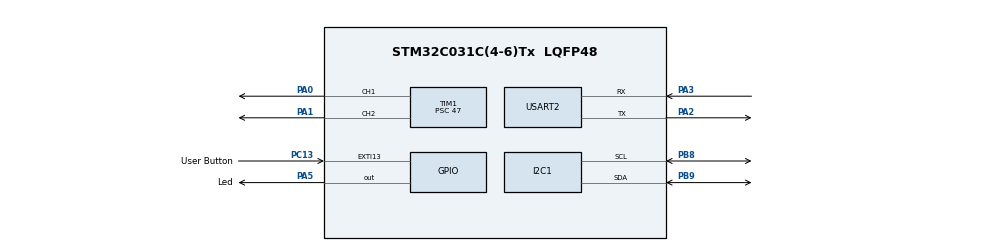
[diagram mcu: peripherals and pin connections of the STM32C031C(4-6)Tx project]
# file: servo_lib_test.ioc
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I2C1.Timing=0x20303E5D
Mcu.Family=STM32C0
Mcu.Name=STM32C031C(4-6)Tx
Mcu.Package=LQFP48
NVIC.EXTI4_15_IRQn=true\:0\:0\:false\:false\:true\:true\:true\:true
PA0.Signal=S_TIM1_CH1
PA1.Signal=S_TIM1_CH2
PA13.Mode=Serial_Wire
PA13.Signal=DEBUG_SWDIO
PA14-BOOT0.Mode=Serial_Wire
PA14-BOOT0.Signal=DEBUG_SWCLK
PA2.Mode=Asynchronous
PA2.Signal=USART2_TX
PA3.Mode=Asynchronous
PA3.Signal=USART2_RX
PA5.GPIO_Label=Led
PA5.GPIO_Speed=GPIO_SPEED_FREQ_VERY_HIGH
PA5.PinState=GPIO_PIN_SET
PA5.Signal=GPIO_Output
PB8.Mode=I2C
PB8.Signal=I2C1_SCL
PB9.Mode=I2C
PB9.Signal=I2C1_SDA
PC13.GPIO_Label=User Button
PC13.Signal=GPXTI13
PC14-OSCX_IN\ (PC14).Mode=LSE-External-Oscillator
PC14-OSCX_IN\ (PC14).Signal=RCC_OSCX_IN
PC15-OSCX_OUT\ (PC15).Mode=LSE-External-Oscillator
PC15-OSCX_OUT\ (PC15).Signal=RCC_OSCX_OUT
PF0-OSC_IN\ (PF0).Mode=HSE-External-Oscillator
PF0-OSC_IN\ (PF0).Signal=RCC_OSC_IN
PF1-OSC_OUT\ (PF1).Mode=HSE-External-Oscillator
PF1-OSC_OUT\ (PF1).Signal=RCC_OSC_OUT
ProjectManager.HeapSize=0x200
ProjectManager.StackSize=0x400
ProjectManager.TargetToolchain=STM32CubeIDE
RCC.ADCFreq_Value=48000000
RCC.AHBFreq_Value=48000000
RCC.CortexFreq_Value=48000000
RCC.EXTERNAL_CLOCK_VALUE=12288000
RCC.HCLKFreq_Value=48000000
RCC.HSE_VALUE=48000000
RCC.HSISYSCLKDivider=RCC_HSI_DIV1
RCC.HSI_VALUE=48000000
RCC.SYSCLKFreq_VALUE=48000000
SH.S_TIM1_CH1.0=TIM1_CH1,PWM Generation1 CH1
SH.S_TIM1_CH2.0=TIM1_CH2,PWM Generation2 CH2
TIM1.Channel-PWM\ Generation1\ CH1=TIM_CHANNEL_1
TIM1.Channel-PWM\ Generation2\ CH2=TIM_CHANNEL_2
TIM1.Period=256
TIM1.Prescaler=47
TIM1.Pulse-PWM\ Generation1\ CH1=0
TIM1.Pulse-PWM\ Generation2\ CH2=0
USART2.VirtualMode-Asynchronous=VM_ASYNC
VP_TIM1_VS_ClockSourceINT.Mode=Internal
board=NUCLEO-C031C6

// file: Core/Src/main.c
/* USER CODE BEGIN Header */
/**
  ******************************************************************************
  * @file           : main.c
  * @brief          : Main program body
  ******************************************************************************
  * @attention
  *
  * Copyright (c) 2024 STMicroelectronics.
  * All rights reserved.
  *
  * This software is licensed under terms that can be found in the LICENSE file
  * in the root directory of this software component.
  * If no LICENSE file comes with this software, it is provided AS-IS.
  *
  ******************************************************************************
  */
/* USER CODE END Header */
#include "main.h"

/* USER CODE BEGIN Includes */
#include "servo.h"
/* USER CODE END Includes */

I2C_HandleTypeDef hi2c1;

TIM_HandleTypeDef htim1;

UART_HandleTypeDef huart2;

void SystemClock_Config(void);
static void MX_GPIO_Init(void);
static void MX_USART2_UART_Init(void);
static void MX_I2C1_Init(void);
static void MX_TIM1_Init(void);

/* USER CODE BEGIN 0 */
uint32_t pwm1, cycle = 4096, pwm2;
Servo myServo1, myServo2;
/* USER CODE END 0 */

int main(void)
{

  /* MCU Configuration--------------------------------------------------------*/

  /* Reset of all peripherals, Initializes the Flash interface and the Systick. */
  HAL_Init();

  /* Configure the system clock */
  SystemClock_Config();

  /* Initialize all configured peripherals */
  MX_GPIO_Init();
  MX_USART2_UART_Init();
  MX_I2C1_Init();
  MX_TIM1_Init();
  /* USER CODE BEGIN 2 */
  SERVO_INIT(&htim1, cycle);
  Servo_Start(&myServo1, TIM_CHANNEL_1);
  Servo_Start(&myServo2, TIM_CHANNEL_2);
  /* USER CODE END 2 */

  /* Infinite loop */
  /* USER CODE BEGIN WHILE */
  //HAL_TIM_Base_Start(&htim1);
	//HAL_TIM_PWM_Start(&htim1, TIM_CHANNEL_1);
	//HAL_TIM_PWM_Start(&htim1, TIM_CHANNEL_2);
	//HAL_TIM_PWM_Start_DMA(&htim1, TIM_CHANNEL_1, &pwm1, 1);
  while (1)
  {
	  Servo_Write(&myServo1, pwm1);
	  Servo_Write(&myServo2, pwm2);
	  //SERVO_SET_DUTY_CYCLE(cycle);
    /* USER CODE END WHILE */

  }
}

void SystemClock_Config(void)
{
  RCC_OscInitTypeDef RCC_OscInitStruct = {0};
  RCC_ClkInitTypeDef RCC_ClkInitStruct = {0};

  /** Initializes the RCC Oscillators according to the specified parameters
  * in the RCC_OscInitTypeDef structure.
  */
  RCC_OscInitStruct.OscillatorType = RCC_OSCILLATORTYPE_HSI;
  RCC_OscInitStruct.HSIState = RCC_HSI_ON;
  RCC_OscInitStruct.HSIDiv = RCC_HSI_DIV1;
  RCC_OscInitStruct.HSICalibrationValue = RCC_HSICALIBRATION_DEFAULT;
  if (HAL_RCC_OscConfig(&RCC_OscInitStruct) != HAL_OK)
  {
    Error_Handler();
  }

  /** Initializes the CPU, AHB and APB buses clocks
  */
  RCC_ClkInitStruct.ClockType = RCC_CLOCKTYPE_HCLK|RCC_CLOCKTYPE_SYSCLK
                              |RCC_CLOCKTYPE_PCLK1;
  RCC_ClkInitStruct.SYSCLKSource = RCC_SYSCLKSOURCE_HSI;
  RCC_ClkInitStruct.SYSCLKDivider = RCC_SYSCLK_DIV1;
  RCC_ClkInitStruct.AHBCLKDivider = RCC_HCLK_DIV1;
  RCC_ClkInitStruct.APB1CLKDivider = RCC_APB1_DIV1;

  if (HAL_RCC_ClockConfig(&RCC_ClkInitStruct, FLASH_LATENCY_1) != HAL_OK)
  {
    Error_Handler();
  }
}

static void MX_I2C1_Init(void)
{

  hi2c1.Instance = I2C1;
  hi2c1.Init.Timing = 0x20303E5D;
  hi2c1.Init.OwnAddress1 = 0;
  hi2c1.Init.AddressingMode = I2C_ADDRESSINGMODE_7BIT;
  hi2c1.Init.DualAddressMode = I2C_DUALADDRESS_DISABLE;
  hi2c1.Init.OwnAddress2 = 0;
  hi2c1.Init.OwnAddress2Masks = I2C_OA2_NOMASK;
  hi2c1.Init.GeneralCallMode = I2C_GENERALCALL_DISABLE;
  hi2c1.Init.NoStretchMode = I2C_NOSTRETCH_DISABLE;
  if (HAL_I2C_Init(&hi2c1) != HAL_OK)
  {
    Error_Handler();
  }

  /** Configure Analogue filter
  */
  if (HAL_I2CEx_ConfigAnalogFilter(&hi2c1, I2C_ANALOGFILTER_ENABLE) != HAL_OK)
  {
    Error_Handler();
  }

  /** Configure Digital filter
  */
  if (HAL_I2CEx_ConfigDigitalFilter(&hi2c1, 0) != HAL_OK)
  {
    Error_Handler();
  }

}

static void MX_TIM1_Init(void)
{

  TIM_ClockConfigTypeDef sClockSourceConfig = {0};
  TIM_MasterConfigTypeDef sMasterConfig = {0};
  TIM_OC_InitTypeDef sConfigOC = {0};
  TIM_BreakDeadTimeConfigTypeDef sBreakDeadTimeConfig = {0};

  htim1.Instance = TIM1;
  htim1.Init.Prescaler = 47;
  htim1.Init.CounterMode = TIM_COUNTERMODE_UP;
  htim1.Init.Period = 256;
  htim1.Init.ClockDivision = TIM_CLOCKDIVISION_DIV1;
  htim1.Init.RepetitionCounter = 0;
  htim1.Init.AutoReloadPreload = TIM_AUTORELOAD_PRELOAD_DISABLE;
  if (HAL_TIM_Base_Init(&htim1) != HAL_OK)
  {
    Error_Handler();
  }
  sClockSourceConfig.ClockSource = TIM_CLOCKSOURCE_INTERNAL;
  if (HAL_TIM_ConfigClockSource(&htim1, &sClockSourceConfig) != HAL_OK)
  {
    Error_Handler();
  }
  if (HAL_TIM_PWM_Init(&htim1) != HAL_OK)
  {
    Error_Handler();
  }
  sMasterConfig.MasterOutputTrigger = TIM_TRGO_RESET;
  sMasterConfig.MasterOutputTrigger2 = TIM_TRGO2_RESET;
  sMasterConfig.MasterSlaveMode = TIM_MASTERSLAVEMODE_DISABLE;
  if (HAL_TIMEx_MasterConfigSynchronization(&htim1, &sMasterConfig) != HAL_OK)
  {
    Error_Handler();
  }
  sConfigOC.OCMode = TIM_OCMODE_PWM1;
  sConfigOC.Pulse = 0;
  sConfigOC.OCPolarity = TIM_OCPOLARITY_HIGH;
  sConfigOC.OCNPolarity = TIM_OCNPOLARITY_HIGH;
  sConfigOC.OCFastMode = TIM_OCFAST_DISABLE;
  sConfigOC.OCIdleState = TIM_OCIDLESTATE_RESET;
  sConfigOC.OCNIdleState = TIM_OCNIDLESTATE_RESET;
  if (HAL_TIM_PWM_ConfigChannel(&htim1, &sConfigOC, TIM_CHANNEL_1) != HAL_OK)
  {
    Error_Handler();
  }
  if (HAL_TIM_PWM_ConfigChannel(&htim1, &sConfigOC, TIM_CHANNEL_2) != HAL_OK)
  {
    Error_Handler();
  }
  sBreakDeadTimeConfig.OffStateRunMode = TIM_OSSR_DISABLE;
  sBreakDeadTimeConfig.OffStateIDLEMode = TIM_OSSI_DISABLE;
  sBreakDeadTimeConfig.LockLevel = TIM_LOCKLEVEL_OFF;
  sBreakDeadTimeConfig.DeadTime = 0;
  sBreakDeadTimeConfig.BreakState = TIM_BREAK_DISABLE;
  sBreakDeadTimeConfig.BreakPolarity = TIM_BREAKPOLARITY_HIGH;
  sBreakDeadTimeConfig.BreakFilter = 0;
  sBreakDeadTimeConfig.BreakAFMode = TIM_BREAK_AFMODE_INPUT;
  sBreakDeadTimeConfig.Break2State = TIM_BREAK2_DISABLE;
  sBreakDeadTimeConfig.Break2Polarity = TIM_BREAK2POLARITY_HIGH;
  sBreakDeadTimeConfig.Break2Filter = 0;
  sBreakDeadTimeConfig.Break2AFMode = TIM_BREAK_AFMODE_INPUT;
  sBreakDeadTimeConfig.AutomaticOutput = TIM_AUTOMATICOUTPUT_DISABLE;
  if (HAL_TIMEx_ConfigBreakDeadTime(&htim1, &sBreakDeadTimeConfig) != HAL_OK)
  {
    Error_Handler();
  }
  HAL_TIM_MspPostInit(&htim1);

}

static void MX_USART2_UART_Init(void)
{

  huart2.Instance = USART2;
  huart2.Init.BaudRate = 115200;
  huart2.Init.WordLength = UART_WORDLENGTH_8B;
  huart2.Init.StopBits = UART_STOPBITS_1;
  huart2.Init.Parity = UART_PARITY_NONE;
  huart2.Init.Mode = UART_MODE_TX_RX;
  huart2.Init.HwFlowCtl = UART_HWCONTROL_NONE;
  huart2.Init.OverSampling = UART_OVERSAMPLING_16;
  huart2.Init.OneBitSampling = UART_ONE_BIT_SAMPLE_DISABLE;
  huart2.Init.ClockPrescaler = UART_PRESCALER_DIV1;
  huart2.AdvancedInit.AdvFeatureInit = UART_ADVFEATURE_NO_INIT;
  if (HAL_UART_Init(&huart2) != HAL_OK)
  {
    Error_Handler();
  }

}

static void MX_GPIO_Init(void)
{
  GPIO_InitTypeDef GPIO_InitStruct = {0};

  /* GPIO Ports Clock Enable */
  __HAL_RCC_GPIOC_CLK_ENABLE();
  __HAL_RCC_GPIOF_CLK_ENABLE();
  __HAL_RCC_GPIOA_CLK_ENABLE();
  __HAL_RCC_GPIOB_CLK_ENABLE();

  /*Configure GPIO pin Output Level */
  HAL_GPIO_WritePin(Led_GPIO_Port, Led_Pin, GPIO_PIN_SET);

  /*Configure GPIO pin : User_Button_Pin */
  GPIO_InitStruct.Pin = User_Button_Pin;
  GPIO_InitStruct.Mode = GPIO_MODE_IT_RISING;
  GPIO_InitStruct.Pull = GPIO_NOPULL;
  HAL_GPIO_Init(User_Button_GPIO_Port, &GPIO_InitStruct);

  /*Configure GPIO pin : Led_Pin */
  GPIO_InitStruct.Pin = Led_Pin;
  GPIO_InitStruct.Mode = GPIO_MODE_OUTPUT_PP;
  GPIO_InitStruct.Pull = GPIO_NOPULL;
  GPIO_InitStruct.Speed = GPIO_SPEED_FREQ_VERY_HIGH;
  HAL_GPIO_Init(Led_GPIO_Port, &GPIO_InitStruct);

  /* EXTI interrupt init*/
  HAL_NVIC_SetPriority(EXTI4_15_IRQn, 0, 0);
  HAL_NVIC_EnableIRQ(EXTI4_15_IRQn);

}

void Error_Handler(void)
{
  __disable_irq();
  while (1)
  {
  }
}
